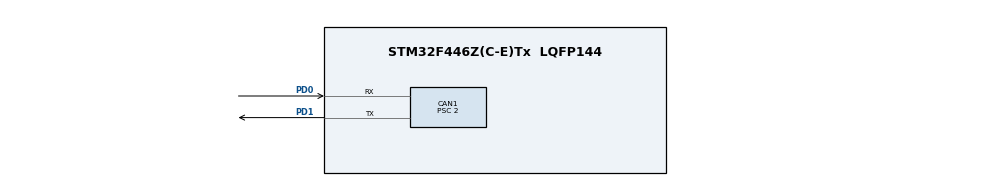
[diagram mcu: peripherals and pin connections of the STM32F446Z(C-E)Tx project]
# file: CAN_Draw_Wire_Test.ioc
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CAN1.BS1=CAN_BS1_12TQ
CAN1.BS2=CAN_BS2_3TQ
CAN1.CalculateBaudRate=500000
CAN1.CalculateTimeBit=2000
CAN1.CalculateTimeQuantum=125.0
CAN1.Mode=CAN_MODE_NORMAL
CAN1.Prescaler=2
Mcu.Family=STM32F4
Mcu.Name=STM32F446Z(C-E)Tx
Mcu.Package=LQFP144
NVIC.CAN1_RX0_IRQn=true\:0\:0\:false\:false\:true\:true\:true\:true
NVIC.PriorityGroup=NVIC_PRIORITYGROUP_4
PD0.GPIO_PuPd=GPIO_NOPULL
PD0.Mode=CAN_Activate
PD0.Signal=CAN1_RX
PD1.Mode=CAN_Activate
PD1.Signal=CAN1_TX
ProjectManager.HeapSize=0x200
ProjectManager.StackSize=0x400
ProjectManager.TargetToolchain=STM32CubeIDE
RCC.CortexFreq_Value=16000000
RCC.USBFreq_Value=96000000
RCC.VCOOutputFreq_Value=192000000
board=custom

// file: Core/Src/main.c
/* USER CODE BEGIN Header */
/**
  ******************************************************************************
  * @file           : main.c
  * @brief          : Main program body
  ******************************************************************************
  * @attention
  *
  * Copyright (c) 2026 STMicroelectronics.
  * All rights reserved.
  *
  * This software is licensed under terms that can be found in the LICENSE file
  * in the root directory of this software component.
  * If no LICENSE file comes with this software, it is provided AS-IS.
  *
  ******************************************************************************
  */
/* USER CODE END Header */
#include "main.h"

CAN_HandleTypeDef hcan1;

/* USER CODE BEGIN PV */

CAN_TxHeaderTypeDef   TxHeader; /* Header containing the information of the transmitted frame */
CAN_RxHeaderTypeDef   RxHeader; ; /* Header containing the information of the received frame */
uint8_t               TxData[8] = {0};  /* Buffer of the data to send */
uint8_t               RxData[8]; /* Buffer of the received data */
uint32_t              TxMailbox;  /* The number of the mail box that transmitted the Tx message */

uint32_t encoderValue = 0;
uint32_t transmitCount = 0;
uint32_t receiveCount = 0;

/* USER CODE END PV */

void SystemClock_Config(void);
static void MX_GPIO_Init(void);
static void MX_CAN1_Init(void);

int main(void)
{

  /* MCU Configuration--------------------------------------------------------*/

  /* Reset of all peripherals, Initializes the Flash interface and the Systick. */
  HAL_Init();

  /* Configure the system clock */
  SystemClock_Config();

  /* Initialize all configured peripherals */
  MX_GPIO_Init();
  MX_CAN1_Init();
  /* USER CODE BEGIN 2 */

  TxHeader.StdId = 0x1;
  	TxHeader.RTR = CAN_RTR_DATA;
  	TxHeader.IDE = CAN_ID_STD;
  	TxHeader.DLC = 8;
  	TxHeader.TransmitGlobalTime = DISABLE;
  	TxData[0] = 0x04; //Data length
	TxData[1] = 0x01; //Encoder address(default 0x01)
	TxData[2] = 0x01; //Instruction code(0x04 = Set the encoder mode
	TxData[3] = 0x00; //Automatic return mode
  /* USER CODE END 2 */

  /* Infinite loop */
  /* USER CODE BEGIN WHILE */
    while (1)
    {
        /* It's mandatory to look for a free Tx mail box */
  	  while(HAL_CAN_GetTxMailboxesFreeLevel(&hcan1) == 0); /* Wait till a Tx mailbox is free. Using while loop instead of HAL_Delay() */
        if (HAL_CAN_AddTxMessage(&hcan1, &TxHeader, TxData, &TxMailbox) != HAL_OK)
        {
          /* Transmission request Error */
          Error_Handler();
        }
        transmitCount ++;
        HAL_Delay(100);
    /* USER CODE END WHILE */

  }
}

void SystemClock_Config(void)
{
  RCC_OscInitTypeDef RCC_OscInitStruct = {0};
  RCC_ClkInitTypeDef RCC_ClkInitStruct = {0};

  /** Configure the main internal regulator output voltage
  */
  __HAL_RCC_PWR_CLK_ENABLE();
  __HAL_PWR_VOLTAGESCALING_CONFIG(PWR_REGULATOR_VOLTAGE_SCALE3);

  /** Initializes the RCC Oscillators according to the specified parameters
  * in the RCC_OscInitTypeDef structure.
  */
  RCC_OscInitStruct.OscillatorType = RCC_OSCILLATORTYPE_HSI;
  RCC_OscInitStruct.HSIState = RCC_HSI_ON;
  RCC_OscInitStruct.HSICalibrationValue = RCC_HSICALIBRATION_DEFAULT;
  RCC_OscInitStruct.PLL.PLLState = RCC_PLL_NONE;
  if (HAL_RCC_OscConfig(&RCC_OscInitStruct) != HAL_OK)
  {
    Error_Handler();
  }

  /** Initializes the CPU, AHB and APB buses clocks
  */
  RCC_ClkInitStruct.ClockType = RCC_CLOCKTYPE_HCLK|RCC_CLOCKTYPE_SYSCLK
                              |RCC_CLOCKTYPE_PCLK1|RCC_CLOCKTYPE_PCLK2;
  RCC_ClkInitStruct.SYSCLKSource = RCC_SYSCLKSOURCE_HSI;
  RCC_ClkInitStruct.AHBCLKDivider = RCC_SYSCLK_DIV1;
  RCC_ClkInitStruct.APB1CLKDivider = RCC_HCLK_DIV1;
  RCC_ClkInitStruct.APB2CLKDivider = RCC_HCLK_DIV1;

  if (HAL_RCC_ClockConfig(&RCC_ClkInitStruct, FLASH_LATENCY_0) != HAL_OK)
  {
    Error_Handler();
  }
}

static void MX_CAN1_Init(void)
{

  /* USER CODE BEGIN CAN1_Init 0 */

	CAN_FilterTypeDef  sFilterConfig;

  /* USER CODE END CAN1_Init 0 */

  hcan1.Instance = CAN1;
  hcan1.Init.Prescaler = 2;
  hcan1.Init.Mode = CAN_MODE_NORMAL;
  hcan1.Init.SyncJumpWidth = CAN_SJW_1TQ;
  hcan1.Init.TimeSeg1 = CAN_BS1_12TQ;
  hcan1.Init.TimeSeg2 = CAN_BS2_3TQ;
  hcan1.Init.TimeTriggeredMode = DISABLE;
  hcan1.Init.AutoBusOff = DISABLE;
  hcan1.Init.AutoWakeUp = DISABLE;
  hcan1.Init.AutoRetransmission = DISABLE;
  hcan1.Init.ReceiveFifoLocked = DISABLE;
  hcan1.Init.TransmitFifoPriority = DISABLE;
  if (HAL_CAN_Init(&hcan1) != HAL_OK)
  {
    Error_Handler();
  }
  /* USER CODE BEGIN CAN1_Init 2 */

  /* The CAN filter configuration */
    sFilterConfig.FilterBank = 0;
    sFilterConfig.FilterMode = CAN_FILTERMODE_IDMASK;
    sFilterConfig.FilterScale = CAN_FILTERSCALE_32BIT;
    sFilterConfig.FilterIdHigh = 0x0000;
    sFilterConfig.FilterIdLow = 0x0000;
    sFilterConfig.FilterMaskIdHigh = 0x0000;
    sFilterConfig.FilterMaskIdLow = 0x0000;
    sFilterConfig.FilterFIFOAssignment = CAN_RX_FIFO0; /* The data will be received in FIFO0 */
    sFilterConfig.FilterActivation = ENABLE;
    sFilterConfig.SlaveStartFilterBank = 14;
    if (HAL_CAN_ConfigFilter(&hcan1, &sFilterConfig) != HAL_OK)
    {
      /* Filter configuration Error */
      Error_Handler();
    }
   /* Starting the CAN peripheral */
    if (HAL_CAN_Start(&hcan1) != HAL_OK)
    {
      /* Start Error */
      Error_Handler();
    }
   /* Activate CAN RX notification on FIFO0 */
    if (HAL_CAN_ActivateNotification(&hcan1, CAN_IT_RX_FIFO0_MSG_PENDING) != HAL_OK)
    {
      /* Notification Error */
      Error_Handler();
    }

  /* USER CODE END CAN1_Init 2 */

}

static void MX_GPIO_Init(void)
{

  /* GPIO Ports Clock Enable */
  __HAL_RCC_GPIOD_CLK_ENABLE();

}

/* USER CODE BEGIN 4 */

void HAL_CAN_RxFifo0MsgPendingCallback(CAN_HandleTypeDef *CanHandle)
{
	/* Get RX message */
	  if (HAL_CAN_GetRxMessage(CanHandle, CAN_RX_FIFO0, &RxHeader, RxData) != HAL_OK)
	  {
		/* Reception Error */
		Error_Handler();
	  }

	  receiveCount ++;
	if(RxData[2] == 0x01)
	{
		encoderValue = RxData[3] | (RxData[4] << 8) | (RxData[5] << 16);
	}

}

/* USER CODE END 4 */

void Error_Handler(void)
{
  __disable_irq();
  while (1)
  {
  }
}
